VERSION ""
NS_ :

BS_:
BU_: Sender Receiver

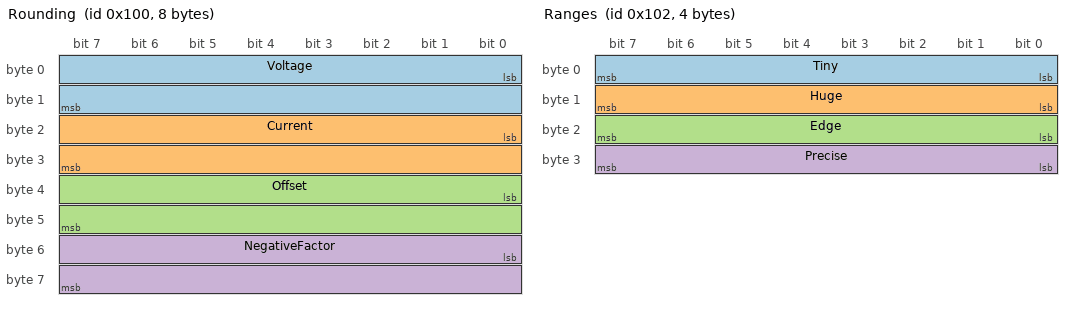
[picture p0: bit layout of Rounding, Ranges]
BO_ 256 Rounding: 8 Sender
 SG_ Voltage : 0|16@1+ (0.1,0) [0|6553.5] "V" Receiver
 SG_ Current : 16|16@1- (0.1,0) [-3276.8|3276.7] "A" Receiver
 SG_ Offset : 32|16@1- (0.5,-40.25) [-16424.25|16343.25] "" Receiver
 SG_ NegativeFactor : 48|16@1- (-0.5,2.25) [-16381.25|16386.25] "" Receiver

BO_ 257 IntegerScaling: 2 Sender
 SG_ Temperature : 0|8@1+ (1,-40) [-40|215] "degC" Receiver
 SG_ Scaled : 8|8@1+ (2,0) [0|510] "" Receiver

BO_ 258 Ranges: 4 Sender
 SG_ Tiny : 0|8@1+ (1E-011,0) [0|1E-010] "" Receiver
 SG_ Huge : 8|8@1+ (1E+018,0) [0|1E+020] "" Receiver
 SG_ Edge : 16|8@1+ (1,0) [0|9007199254740992] "" Receiver
 SG_ Precise : 24|8@1+ (0.5,0) [0|16777216.5] "" Receiver
